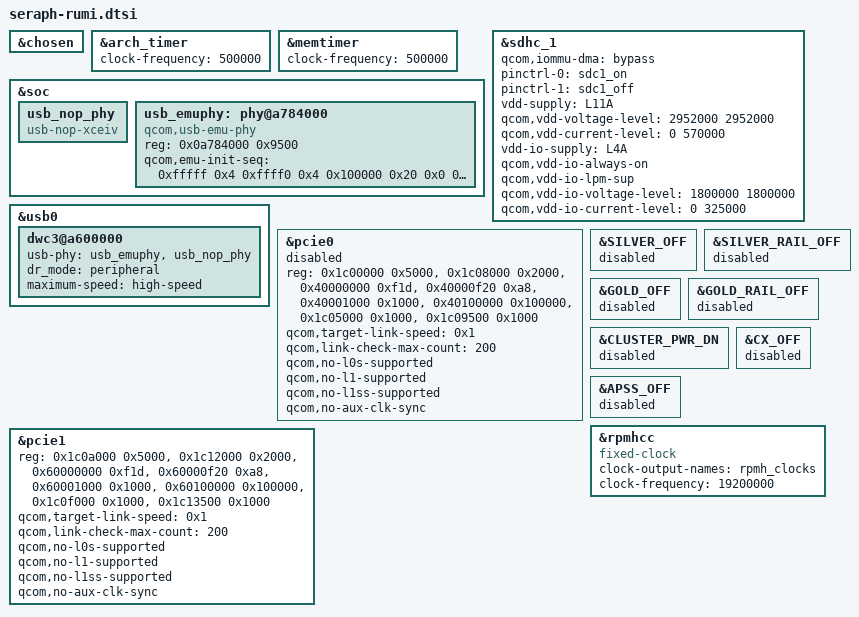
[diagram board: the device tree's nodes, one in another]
&chosen {
};

&arch_timer {
	clock-frequency = <500000>;
};

&memtimer {
	clock-frequency = <500000>;
};

&soc {
	usb_nop_phy: usb_nop_phy {
		compatible = "usb-nop-xceiv";
	};

	usb_emuphy: phy@a784000 {
		compatible = "qcom,usb-emu-phy";
		reg = <0x0a784000 0x9500>;

		qcom,emu-init-seq = <0xfffff 0x4
			0xffff0 0x4
			0x100000 0x20
			0x0 0x20
			0x000101F0 0x20
			0x00100000 0x3c
			0x0 0x3c
			0x0 0x4>;
	};
};

&sdhc_1 {
	status = "ok";

	qcom,iommu-dma = "bypass";

	pinctrl-names = "default", "sleep";
	pinctrl-0 = <&sdc1_on>;
	pinctrl-1 = <&sdc1_off>;

	vdd-supply = <&L11A>;
	qcom,vdd-voltage-level = <2952000 2952000>;
	qcom,vdd-current-level = <0 570000>;

	vdd-io-supply = <&L4A>;
	qcom,vdd-io-always-on;
	qcom,vdd-io-lpm-sup;
	qcom,vdd-io-voltage-level = <1800000 1800000>;
	qcom,vdd-io-current-level = <0 325000>;
};

&usb0 {
	dwc3@a600000 {
		usb-phy = <&usb_emuphy>, <&usb_nop_phy>;
		dr_mode = "peripheral";
		maximum-speed = "high-speed";
	};
};

&pcie0 {
	status = "disabled";
	reg = <0x1c00000 0x5000>,
		<0x1c08000 0x2000>,
		<0x40000000 0xf1d>,
		<0x40000f20 0xa8>,
		<0x40001000 0x1000>,
		<0x40100000 0x100000>,
		<0x1c05000 0x1000>,
		<0x1c09500 0x1000>;
		reg-names = "parf", "phy", "dm_core", "elbi", "iatu", "conf", "mhi",
			"rumi";
		qcom,target-link-speed = <0x1>;
		qcom,link-check-max-count = <200>; /* 1 sec */
		qcom,no-l0s-supported;
		qcom,no-l1-supported;
		qcom,no-l1ss-supported;
		qcom,no-aux-clk-sync;
};

&pcie1 {
	status = "ok";
	reg = <0x1c0a000 0x5000>,
		<0x1c12000 0x2000>,
		<0x60000000 0xf1d>,
		<0x60000f20 0xa8>,
		<0x60001000 0x1000>,
		<0x60100000 0x100000>,
		<0x1c0f000 0x1000>,
		<0x1c13500 0x1000>;
		reg-names = "parf", "phy", "dm_core", "elbi", "iatu", "conf", "mhi",
			"rumi";
		qcom,target-link-speed = <0x1>;
		qcom,link-check-max-count = <200>; /* 1 sec */
		qcom,no-l0s-supported;
		qcom,no-l1-supported;
		qcom,no-l1ss-supported;
		qcom,no-aux-clk-sync;
};

&SILVER_OFF {
	status = "disabled";
};

&SILVER_RAIL_OFF {
	status = "disabled";
};

&GOLD_OFF {
	status = "disabled";
};

&GOLD_RAIL_OFF {
	status = "disabled";
};

&CLUSTER_PWR_DN {
	status = "disabled";
};

&CX_OFF {
	status = "disabled";
};

&APSS_OFF {
	status = "disabled";
};

&rpmhcc {
	compatible = "fixed-clock";
	clock-output-names = "rpmh_clocks";
	clock-frequency = <19200000>;
};
